# RX64M_SDHI_Pilot register map
File version: 1.0
RX64M_SDHI_Pilot peripheral registers generated from iodefine.h (pilot).
Registers are 32-bit, read-write, reset 0x0 unless marked. A register's access mark holds for its fields unless they carry their own. Offsets are from the block's base; lines under a group give offsets from that group; [hi:lo] are bit positions; {n}, {i} and the like mark numbered series; 'fields as' and 'values as' point back to an identical list; <NAME> marks a mode.

## Memory map
0x0008AC00 SDHI size 0x1E4

## SDHI
Base 0x0008AC00
0x00 SDCMD
0x08 SDARG
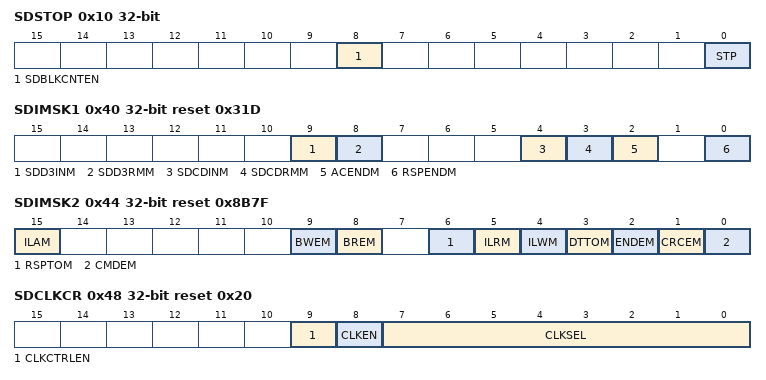
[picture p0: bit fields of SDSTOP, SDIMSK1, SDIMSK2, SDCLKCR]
0x10 SDSTOP
  [8] SDBLKCNTEN, [0] STP
0x14 SDBLKCNT
0x18 SDRSP10 ro
0x20 SDRSP32 ro
0x28 SDRSP54 ro
0x30 SDRSP76 ro
0x38 SDSTS1 (reset mask 0xFFFFFB5F)
0x3C SDSTS2 reset 0x2000 (reset mask 0xFFFFFF7F)
0x40 SDIMSK1 reset 0x31D
  [9] SDD3INM, [8] SDD3RMM, [4] SDCDINM, [3] SDCDRMM, [2] ACENDM, [0] RSPENDM
0x44 SDIMSK2 reset 0x8B7F
  [15] ILAM, [9] BWEM, [8] BREM, [6] RSPTOM, [5] ILRM, [4] ILWM, [3] DTTOM, [2] ENDEM, [1] CRCEM, [0] CMDEM
0x48 SDCLKCR reset 0x20
  [9] CLKCTRLEN, [8] CLKEN, [7:0] CLKSEL
0x4C SDSIZE
  [9:0] LEN
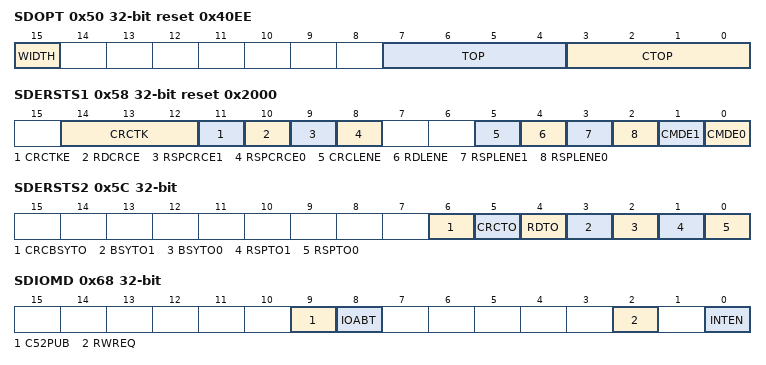
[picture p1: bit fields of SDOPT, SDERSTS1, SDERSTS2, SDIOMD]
0x50 SDOPT reset 0x40EE
  [15] WIDTH, [7:4] TOP, [3:0] CTOP
0x58 SDERSTS1 ro reset 0x2000
  [14:12] CRCTK, [11] CRCTKE, [10] RDCRCE, [9] RSPCRCE1, [8] RSPCRCE0, [5] CRCLENE, [4] RDLENE, [3] RSPLENE1, [2] RSPLENE0, [1] CMDE1, [0] CMDE0
0x5C SDERSTS2 ro
  [6] CRCBSYTO, [5] CRCTO, [4] RDTO, [3] BSYTO1, [2] BSYTO0, [1] RSPTO1, [0] RSPTO0
0x60 SDBUFR reset not defined
0x68 SDIOMD
  [9] C52PUB, [8] IOABT, [2] RWREQ, [0] INTEN
0x6C SDIOSTS (reset mask 0xFFFFFFF9)
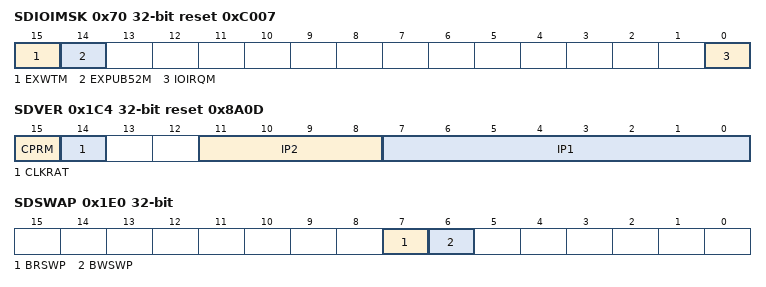
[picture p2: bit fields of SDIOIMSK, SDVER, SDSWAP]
0x70 SDIOIMSK reset 0xC007
  [15] EXWTM, [14] EXPUB52M, [0] IOIRQM
0x1B0 SDDMAEN reset 0x1010
  [1] DMAEN
0x1C0 SDRST reset 0x7
  [0] SDRST
0x1C4 SDVER ro reset 0x8A0D
  [15] CPRM, [14] CLKRAT, [11:8] IP2, [7:0] IP1
0x1E0 SDSWAP
  [7] BRSWP, [6] BWSWP
